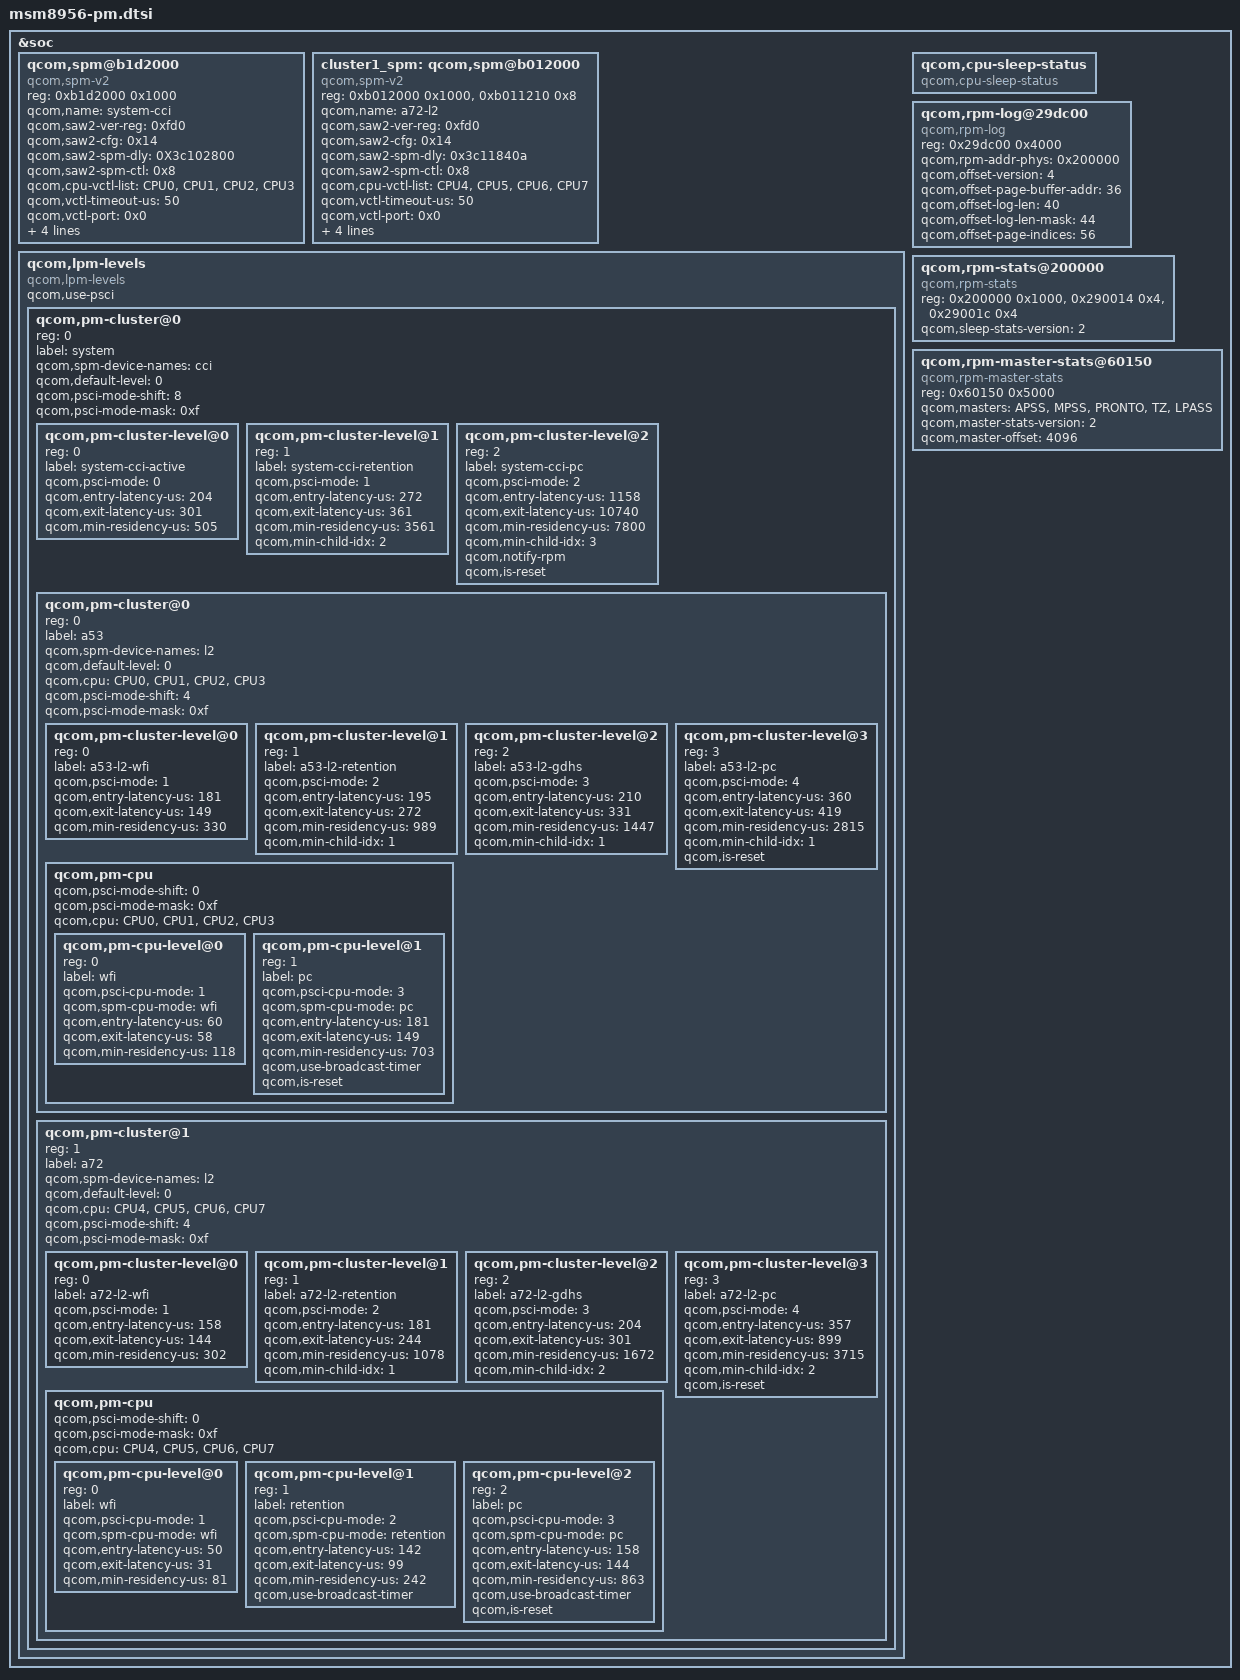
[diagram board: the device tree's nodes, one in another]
/* Copyright (c) 2015-2016, The Linux Foundation. All rights reserved.
 *
 * This program is free software; you can redistribute it and/or modify
 * it under the terms of the GNU General Public License version 2 and
 * only version 2 as published by the Free Software Foundation.
 *
 * This program is distributed in the hope that it will be useful,
 * but WITHOUT ANY WARRANTY; without even the implied warranty of
 * MERCHANTABILITY or FITNESS FOR A PARTICULAR PURPOSE.  See the
 * GNU General Public License for more details.
 */

&soc {
	qcom,spm@b1d2000 {
		compatible = "qcom,spm-v2";
		#address-cells = <1>;
		#size-cells = <1>;
		reg = <0xb1d2000 0x1000>;
		qcom,name = "system-cci"; /* CCI SAW */
		qcom,saw2-ver-reg = <0xfd0>;
		qcom,saw2-cfg = <0x14>;
		qcom,saw2-spm-dly = <0X3c102800>;
		qcom,saw2-spm-ctl = <0x8>;
		qcom,cpu-vctl-list = <&CPU0 &CPU1 &CPU2 &CPU3>;
		qcom,vctl-timeout-us = <50>;
		qcom,vctl-port = <0x0>;
		qcom,phase-port = <0x1>;
		qcom,saw2-pmic-data0 = <0x03030080>; /* VDD_APC0 on */
		qcom,saw2-pmic-data1 = <0x00030000>; /* VDD_APC0 off  */
		qcom,pfm-port = <0x2>;
	};

	cluster1_spm: qcom,spm@b012000 {
		compatible = "qcom,spm-v2";
		#address-cells = <1>;
		#size-cells = <1>;
		reg = <0xb012000 0x1000>,
		    <0xb011210 0x8>; /* SPM_QCHANNEL_CFG */
		qcom,name = "a72-l2"; /* A5x L2 SAW */
		qcom,saw2-ver-reg = <0xfd0>;
		qcom,saw2-cfg = <0x14>;
		qcom,saw2-spm-dly = <0x3c11840a>;
		qcom,saw2-spm-ctl = <0x8>;
		qcom,cpu-vctl-list = <&CPU4 &CPU5 &CPU6 &CPU7>;
		qcom,vctl-timeout-us = <50>;
		qcom,vctl-port = <0x0>;
		qcom,phase-port = <0x1>;
		qcom,saw2-pmic-data0 = <0x03030080>; /* VDD_APC1 on */
		qcom,saw2-pmic-data1 = <0x00030000>; /* VDD_APC1 off  */
		qcom,pfm-port = <0x2>;
	};

	qcom,lpm-levels {
		status = "okay";
		compatible = "qcom,lpm-levels";
		qcom,use-psci;
		#address-cells = <1>;
		#size-cells = <0>;

		qcom,pm-cluster@0 {
			reg = <0>;
			#address-cells = <1>;
			#size-cells = <0>;
			label = "system";
			qcom,spm-device-names = "cci";
			qcom,default-level = <0>;
			qcom,psci-mode-shift = <8>;
			qcom,psci-mode-mask = <0xf>;

			qcom,pm-cluster-level@0{
				reg = <0>;
				label = "system-cci-active";
				qcom,psci-mode = <0>;
				qcom,entry-latency-us = <204>;
				qcom,exit-latency-us = <301>;
				qcom,min-residency-us = <505>;
			};

			qcom,pm-cluster-level@1{
				reg = <1>;
				label = "system-cci-retention";
				qcom,psci-mode = <1>;
				qcom,entry-latency-us = <272>;
				qcom,exit-latency-us = <361>;
				qcom,min-residency-us = <3561>;
				qcom,min-child-idx = <2>;
			};

			qcom,pm-cluster-level@2{
				reg = <2>;
				label = "system-cci-pc";
				qcom,psci-mode = <2>;
				/* TODO: WARNING: time_overhead - last_exit_latency <= 0
				 * Using safe value time_overhead; please recalculate */
				qcom,entry-latency-us = <1158>;
				qcom,exit-latency-us = <10740>;
				qcom,min-residency-us = <7800>;
				qcom,min-child-idx = <3>;
				qcom,notify-rpm;
				qcom,is-reset;
			};

			qcom,pm-cluster@0{
				reg = <0>;
				#address-cells = <1>;
				#size-cells = <0>;
				label = "a53";
				qcom,spm-device-names = "l2";
				qcom,default-level=<0>;
				qcom,cpu = <&CPU0 &CPU1 &CPU2 &CPU3>;
				qcom,psci-mode-shift = <4>;
				qcom,psci-mode-mask = <0xf>;

				qcom,pm-cluster-level@0{
					reg = <0>;
					label = "a53-l2-wfi";
					qcom,psci-mode = <1>;
					qcom,entry-latency-us = <181>;
					qcom,exit-latency-us = <149>;
					qcom,min-residency-us = <330>;
				};

				qcom,pm-cluster-level@1{
					reg = <1>;
					label = "a53-l2-retention";
					qcom,psci-mode = <2>;
					qcom,entry-latency-us = <195>;
					qcom,exit-latency-us = <272>;
					qcom,min-residency-us = <989>;
					qcom,min-child-idx = <1>;
				};

				qcom,pm-cluster-level@2{
					reg = <2>;
					label = "a53-l2-gdhs";
					qcom,psci-mode = <3>;
					qcom,entry-latency-us = <210>;
					qcom,exit-latency-us = <331>;
					qcom,min-residency-us = <1447>;
					qcom,min-child-idx = <1>;
				};

				qcom,pm-cluster-level@3{
					reg = <3>;
					label = "a53-l2-pc";
					qcom,psci-mode = <4>;
					qcom,entry-latency-us = <360>;
					qcom,exit-latency-us = <419>;
					qcom,min-residency-us = <2815>;
					qcom,min-child-idx = <1>;
					qcom,is-reset;
				};

				qcom,pm-cpu {
					#address-cells = <1>;
					#size-cells = <0>;
					qcom,psci-mode-shift = <0>;
					qcom,psci-mode-mask = <0xf>;
					qcom,cpu = <&CPU0 &CPU1 &CPU2 &CPU3>;

					qcom,pm-cpu-level@0 {
						reg = <0>;
						label = "wfi";
						qcom,psci-cpu-mode = <1>;
						qcom,spm-cpu-mode = "wfi";
						qcom,entry-latency-us = <60>;
						qcom,exit-latency-us = <58>;
						qcom,min-residency-us = <118>;
					};

					qcom,pm-cpu-level@1 {
						reg = <1>;
						label = "pc";
						qcom,psci-cpu-mode = <3>;
						qcom,spm-cpu-mode = "pc";
						qcom,entry-latency-us = <181>;
						qcom,exit-latency-us = <149>;
						qcom,min-residency-us = <703>;
						qcom,use-broadcast-timer;
						qcom,is-reset;
					};
				};
			};

			qcom,pm-cluster@1{
				reg = <1>;
				#address-cells = <1>;
				#size-cells = <0>;
				label = "a72";
				qcom,spm-device-names = "l2";
				qcom,default-level=<0>;
				qcom,cpu = <&CPU4 &CPU5 &CPU6 &CPU7>;
				qcom,psci-mode-shift = <4>;
				qcom,psci-mode-mask = <0xf>;

				qcom,pm-cluster-level@0{
					reg = <0>;
					label = "a72-l2-wfi";
					qcom,psci-mode = <1>;
					qcom,entry-latency-us = <158>;
					qcom,exit-latency-us = <144>;
					qcom,min-residency-us = <302>;
				};

				qcom,pm-cluster-level@1{
					reg = <1>;
					label = "a72-l2-retention";
					qcom,psci-mode = <2>;
					qcom,entry-latency-us = <181>;
					qcom,exit-latency-us = <244>;
					qcom,min-residency-us = <1078>;
					qcom,min-child-idx = <1>;
				};

				qcom,pm-cluster-level@2{
					reg = <2>;
					label = "a72-l2-gdhs";
					qcom,psci-mode = <3>;
					qcom,entry-latency-us = <204>;
					qcom,exit-latency-us = <301>;
					qcom,min-residency-us = <1672>;
					qcom,min-child-idx = <2>;
				};

				qcom,pm-cluster-level@3{
					reg = <3>;
					label = "a72-l2-pc";
					qcom,psci-mode = <4>;
					qcom,entry-latency-us = <357>;
					qcom,exit-latency-us = <899>;
					qcom,min-residency-us = <3715>;
					qcom,min-child-idx = <2>;
					qcom,is-reset;
				};

				qcom,pm-cpu {
					#address-cells = <1>;
					#size-cells = <0>;
					qcom,psci-mode-shift = <0>;
					qcom,psci-mode-mask = <0xf>;
					qcom,cpu = <&CPU4 &CPU5 &CPU6 &CPU7>;

					qcom,pm-cpu-level@0 {
						reg = <0>;
						label = "wfi";
						qcom,psci-cpu-mode = <1>;
						qcom,spm-cpu-mode = "wfi";
						qcom,entry-latency-us = <50>;
						qcom,exit-latency-us = <31>;
						qcom,min-residency-us = <81>;
					};

					qcom,pm-cpu-level@1 {
						reg = <1>;
						label = "retention";
						qcom,psci-cpu-mode = <2>;
						qcom,spm-cpu-mode = "retention";
						qcom,entry-latency-us = <142>;
						qcom,exit-latency-us = <99>;
						qcom,min-residency-us = <242>;
						qcom,use-broadcast-timer;
					};

					qcom,pm-cpu-level@2 {
						reg = <2>;
						label = "pc";
						qcom,psci-cpu-mode = <3>;
						qcom,spm-cpu-mode = "pc";
						qcom,entry-latency-us = <158>;
						qcom,exit-latency-us = <144>;
						qcom,min-residency-us = <863>;
						qcom,use-broadcast-timer;
						qcom,is-reset;
					};
				};
			};
		};

	};

	qcom,cpu-sleep-status{
		compatible = "qcom,cpu-sleep-status";
	};

	qcom,rpm-log@29dc00 {
		compatible = "qcom,rpm-log";
		reg = <0x29dc00 0x4000>;
		qcom,rpm-addr-phys = <0x200000>;
		qcom,offset-version = <4>;
		qcom,offset-page-buffer-addr = <36>;
		qcom,offset-log-len = <40>;
		qcom,offset-log-len-mask = <44>;
		qcom,offset-page-indices = <56>;
	};

	qcom,rpm-stats@200000 {
		compatible = "qcom,rpm-stats";
		reg = <0x200000 0x1000>,
		      <0x290014 0x4>,
		      <0x29001c 0x4>;
		reg-names = "phys_addr_base", "offset_addr", "heap_phys_addrbase";
		qcom,sleep-stats-version = <2>;
	};

	qcom,rpm-master-stats@60150 {
		compatible = "qcom,rpm-master-stats";
		reg = <0x60150 0x5000>;
		qcom,masters = "APSS", "MPSS", "PRONTO", "TZ", "LPASS";
		qcom,master-stats-version = <2>;
		qcom,master-offset = <4096>;
	};

/*
	qcom,rpm-rbcpr-stats@0x29daa0  {
		compatible = "qcom,rpmrbcpr-stats";
		reg = <0x29daa0 0x1a0000>;
		qcom,start-offset = <0x190010>;
	};
*/
};
